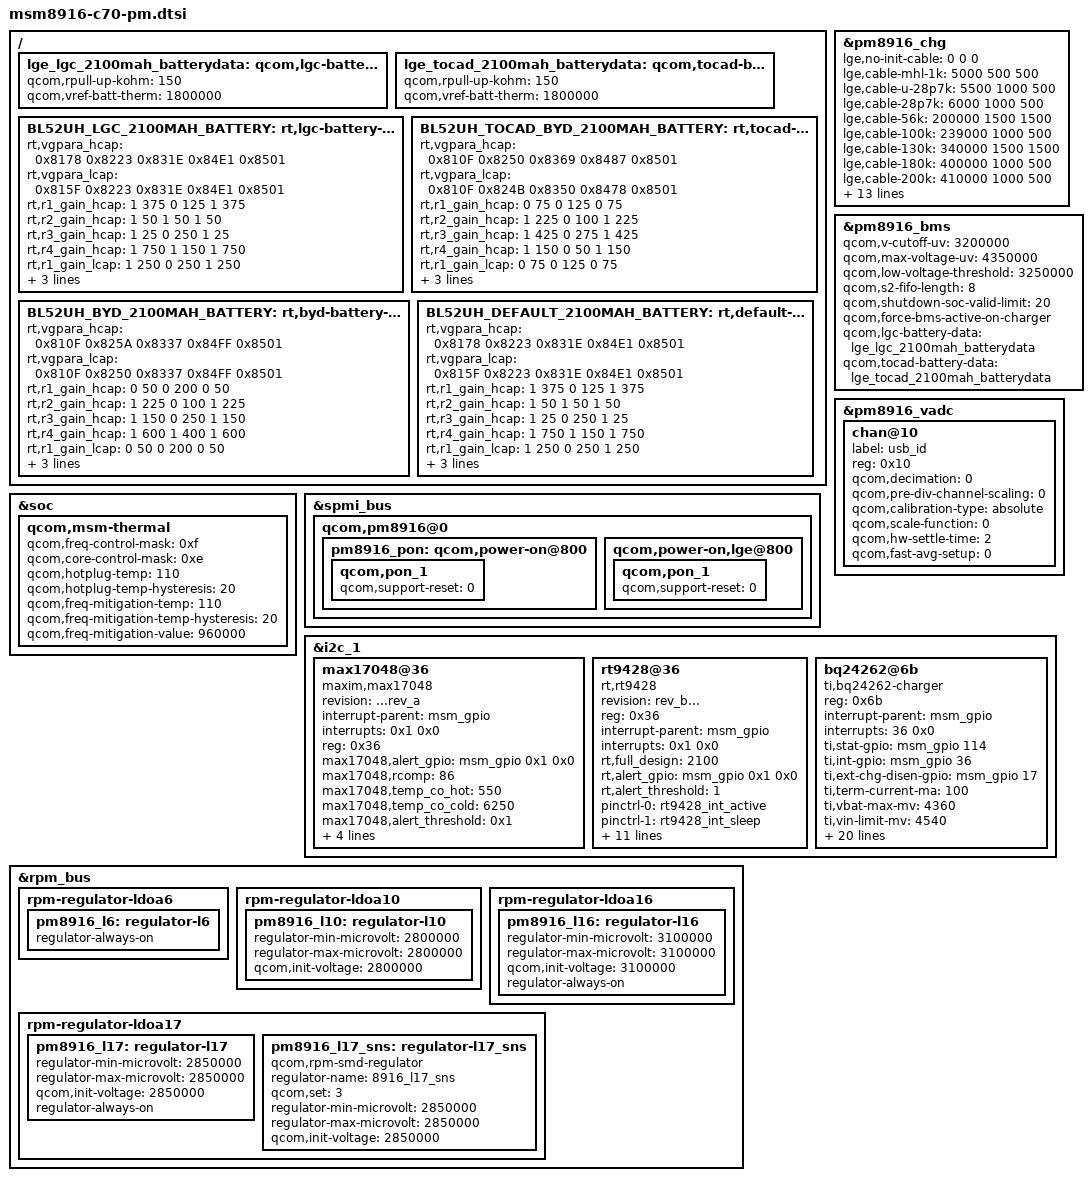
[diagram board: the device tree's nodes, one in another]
/* Copyright (c) 2012, Code Aurora Forum. All rights reserved.
 *
 * This program is free software; you can redistribute it and/or modify
* it under the terms of the GNU General Public License version 2 and
* only version 2 as published by the Free Software Foundation.
*
* This program is distributed in the hope that it will be useful,
* but WITHOUT ANY WARRANTY; without even the implied warranty of
* MERCHANTABILITY or FITNESS FOR A PARTICULAR PURPOSE.  See the
* GNU General Public License for more details.
*/

&pm8916_chg {
	status = "ok";

	lge,no-init-cable = <0 0 0>;
	lge,cable-mhl-1k = <5000 500 500>;
	lge,cable-u-28p7k = <5500 1000 500>;
	lge,cable-28p7k = <6000 1000 500>;
	lge,cable-56k = <200000 1500 1500>;
	lge,cable-100k = <239000 1000 500>;
	lge,cable-130k = <340000 1500 1500>;
	lge,cable-180k = <400000 1000 500>;
	lge,cable-200k = <410000 1000 500>;
	lge,cable-220k = <485000 1000 500>;
	lge,cable-270k = <560000 1000 500>;
	lge,cable-330k = <735000 1000 500>;
	lge,cable-620k = <955000 1000 500>;
	lge,cable-910k = <1140000 1500 1500>;
	lge,cable-none = <1900000 1000  500>;

	qcom,vddmax-mv = <4350>;
	qcom,vddsafe-mv = <4380>;
	qcom,vinmin-mv = <4470>;
	qcom,tchg-mins = <480>;
	qcom,btc-disabled = <1>;
	qcom,resume-soc = <98>;
	qcom,disable-vbatdet-based-recharge;
};

&soc {
	qcom,msm-thermal {
		qcom,freq-control-mask = <0xf>;
		qcom,core-control-mask = <0xe>;
		qcom,hotplug-temp = <110>;
		qcom,hotplug-temp-hysteresis = <20>;
		qcom,freq-mitigation-temp = <110>;
		qcom,freq-mitigation-temp-hysteresis = <20>;
		qcom,freq-mitigation-value = <960000>;
		};
};

&spmi_bus {
qcom,pm8916@0 {
	pm8916_pon: qcom,power-on@800 {
			qcom,pon_1 {
				qcom,support-reset = <0>;
			};
		};
	qcom,power-on,lge@800{
			 qcom,pon_1 {
				qcom,support-reset = <0>;
			};
		};
	};
};

/ {
	lge_lgc_2100mah_batterydata: qcom,lgc-battery-data {
		qcom,rpull-up-kohm = <150>;
		qcom,vref-batt-therm = <1800000>;

		#include "../msm8916-lge-common/batterydata_LGE_lgc_2100mAh_52UH.dtsi"
	};

	lge_tocad_2100mah_batterydata: qcom,tocad-battery-data {
		qcom,rpull-up-kohm = <150>;
		qcom,vref-batt-therm = <1800000>;

		#include "../msm8916-lge-common/batterydata_LGE_tocad_2100mAh_52UH.dtsi"
	};
};

/ {
	BL52UH_LGC_2100MAH_BATTERY: rt,lgc-battery-data {
		rt,vgpara_hcap = <0x8178 0x8223 0x831E 0x84E1 0x8501>;
		rt,vgpara_lcap = <0x815F 0x8223 0x831E 0x84E1 0x8501>;
		rt,r1_gain_hcap = < 1 375 0 125 1 375>;
		rt,r2_gain_hcap = < 1 50  1 50  1 50>;
		rt,r3_gain_hcap = < 1 25  0 250 1 25>;
		rt,r4_gain_hcap = < 1 750 1 150 1 750>;
		rt,r1_gain_lcap = < 1 250 0 250 1 250>;
		rt,r2_gain_lcap = < 1 50  1 50  1 50>;
		rt,r3_gain_lcap = < 1 25  0 250 1 25>;
		rt,r4_gain_lcap = < 1 750 1 150 1 750>;
	};

	BL52UH_TOCAD_BYD_2100MAH_BATTERY: rt,tocad-byd-battery-data {
		rt,vgpara_hcap = <0x810F 0x8250 0x8369 0x8487 0x8501>;
		rt,vgpara_lcap = <0x810F 0x824B 0x8350 0x8478 0x8501>;
		rt,r1_gain_hcap = < 0 75  0 125 0 75>;
		rt,r2_gain_hcap = < 1 225 0 100 1 225>;
		rt,r3_gain_hcap = < 1 425 0 275 1 425>;
		rt,r4_gain_hcap = < 1 150 0 50  1 150>;
		rt,r1_gain_lcap = < 0 75  0 125 0 75>;
		rt,r2_gain_lcap = < 1 200 0 25  1 200>;
		rt,r3_gain_lcap = < 1 300 0 325 1 300>;
		rt,r4_gain_lcap = < 1 75  0 75  1 75>;
	};

	BL52UH_BYD_2100MAH_BATTERY: rt,byd-battery-data {
		rt,vgpara_hcap = <0x810F 0x825A 0x8337 0x84FF 0x8501>;
		rt,vgpara_lcap = <0x810F 0x8250 0x8337 0x84FF 0x8501>;
		rt,r1_gain_hcap = < 0 50 0 200 0 50>;
		rt,r2_gain_hcap = < 1 225  0 100  1 225>;
		rt,r3_gain_hcap = < 1 150  0 250 1 150>;
		rt,r4_gain_hcap = < 1 600 1 400 1 600>;
		rt,r1_gain_lcap = < 0 50 0 200 0 50>;
		rt,r2_gain_lcap = < 1 190  1 90  1 190>;
		rt,r3_gain_lcap = < 1 150  0 250 1 150>;
		rt,r4_gain_lcap = < 1 600 1 400 1 600>;
	};

	BL52UH_DEFAULT_2100MAH_BATTERY: rt,default-battery-data {
		rt,vgpara_hcap = <0x8178 0x8223 0x831E 0x84E1 0x8501>;
		rt,vgpara_lcap = <0x815F 0x8223 0x831E 0x84E1 0x8501>;
		rt,r1_gain_hcap = < 1 375 0 125 1 375>;
		rt,r2_gain_hcap = < 1 50  1 50  1 50>;
		rt,r3_gain_hcap = < 1 25  0 250 1 25>;
		rt,r4_gain_hcap = < 1 750 1 150 1 750>;
		rt,r1_gain_lcap = < 1 250 0 250 1 250>;
		rt,r2_gain_lcap = < 1 50  1 50  1 50>;
		rt,r3_gain_lcap = < 1 25  0 250 1 25>;
		rt,r4_gain_lcap = < 1 750 1 150 1 750>;
	};
};

&pm8916_bms {
	status = "ok";
	qcom,v-cutoff-uv = <3200000>;
	qcom,max-voltage-uv = <4350000>;
	qcom,low-voltage-threshold = <3250000>;
	qcom,s2-fifo-length = <8>;
	qcom,shutdown-soc-valid-limit = <20>;
	qcom,force-bms-active-on-charger;
	qcom,lgc-battery-data = <&lge_lgc_2100mah_batterydata>;
	qcom,tocad-battery-data = <&lge_tocad_2100mah_batterydata>;
};

&pm8916_vadc {
	chan@10 {
		label = "usb_id";
		reg = <0x10>;
		qcom,decimation = <0>;
		qcom,pre-div-channel-scaling = <0>;
		qcom,calibration-type = "absolute";
		qcom,scale-function = <0>;
		qcom,hw-settle-time = <2>;
		qcom,fast-avg-setup = <0>;
	};
};

&i2c_1 {
	max17048@36 {
		status = "ok";
		revision = "...rev_a";
		compatible = "maxim,max17048";
		interrupt-parent = <&msm_gpio>;
		interrupts = <0x1 0x0>;
		reg = <0x36>;
		max17048,alert_gpio = <&msm_gpio 0x1 0x0>;
		max17048,rcomp = <86>;
		max17048,temp_co_hot = <550>;
		max17048,temp_co_cold = <6250>;
		max17048,alert_threshold = <0x1>;
		max17048,full_design = <3200>;
		max17048,empty = <0>;
		pinctrl-names = "default", "sleep";
		pinctrl-0 = <&max17048_int_active>;
		pinctrl-1 = <&max17048_int_sleep>;
	};

	rt9428@36 {
		compatible = "rt,rt9428";
		status = "ok";
		revision = "rev_b...";
		reg = <0x36>;
		interrupt-parent = <&msm_gpio>;
		interrupts = <0x1 0x0>;
		rt,full_design= <2100>;
		rt,alert_gpio = <&msm_gpio 0x1 0x0>;
		rt,alert_threshold = <1>;
		/* Pins config setting */
		pinctrl-names = "default", "sleep";
		pinctrl-0 = <&rt9428_int_active>;
		pinctrl-1 = <&rt9428_int_sleep>;
		rt,soc_comp = <0>;
		rt,vgcomp0 = <0xAB>;
		rt,temp_base = <5 5 25 45>;
		rt,lgc-battery-data = <&BL52UH_LGC_2100MAH_BATTERY>;
		rt,tocad-byd-battery-data = <&BL52UH_TOCAD_BYD_2100MAH_BATTERY>;
		rt,byd-battery-data = <&BL52UH_BYD_2100MAH_BATTERY>;
		rt,default-battery-data = <&BL52UH_DEFAULT_2100MAH_BATTERY>;
	};

	bq24262@6b {
		status = "ok";
		compatible = "ti,bq24262-charger";
		reg = <0x6b>;
		interrupt-parent = <&msm_gpio>;
		interrupts = <36 0x0>;
		ti,stat-gpio = <&msm_gpio 114 0>;
		ti,int-gpio = <&msm_gpio 36 0>;
		ti,ext-chg-disen-gpio = <&msm_gpio 17 0>;
		ti,term-current-ma = <100>;
		ti,vbat-max-mv = <4360>;		/* Step unit 20 mV, battery available voltage(x = 4.375) : x-0.025 ~ x ~ x+0.025 */
		ti,vin-limit-mv = <4540>;
		/* Pins config setting */
		pinctrl-names = "default", "sleep";
		pinctrl-0 = <&bq24262_int_active &bq24262_ext_stat_active>;
		pinctrl-1 = <&bq24262_int_sleep &bq24262_ext_stat_sleep>;

/* Each model is defferently value */
		lge,no-init-cable = <0 0 0>;
		lge,cable-mhl-1k = <5000 500 500>;
		lge,cable-u-28p7k = <5500 1000 500>;
		lge,cable-28p7k = <6000 1000 500>;
		lge,cable-56k = <200000 1500 1500>;
		lge,cable-100k = <239000 1000 500>;
		lge,cable-130k = <340000 1500 1500>;
		lge,cable-180k = <400000 1000 500>;
		lge,cable-200k = <410000 1000 500>;
		lge,cable-220k = <485000 1000 500>;
		lge,cable-270k = <560000 1000 500>;
		lge,cable-330k = <735000 1000 500>;
		lge,cable-620k = <955000 1000 500>;
		lge,cable-910k = <1140000 1500 1500>;
		lge,cable-none = <1900000 1000  500>;

		qcom,bq24262-vadc = <&pm8916_vadc>;
	};
};

&rpm_bus {
	rpm-regulator-ldoa6 {
		status = "okay";
		pm8916_l6: regulator-l6 {
			regulator-always-on;
			status = "okay";
		};
	};

	rpm-regulator-ldoa10 {
		status = "okay";
		pm8916_l10: regulator-l10 {
			regulator-min-microvolt = <2800000>;
			regulator-max-microvolt = <2800000>;
			qcom,init-voltage = <2800000>;
			//regulator-always-on;
			status = "okay";
		};
	};

	rpm-regulator-ldoa16 {
		status = "okay";
		pm8916_l16: regulator-l16 {
			regulator-min-microvolt = <3100000>;
			regulator-max-microvolt = <3100000>;
			qcom,init-voltage = <3100000>;
			regulator-always-on;
			status = "okay";
		};
	};

	rpm-regulator-ldoa17 {
		status = "okay";
		pm8916_l17: regulator-l17 {
			regulator-min-microvolt = <2850000>;
			regulator-max-microvolt = <2850000>;
			qcom,init-voltage = <2850000>;
			regulator-always-on;
			status = "okay";
		};

		pm8916_l17_sns: regulator-l17_sns {
			status = "ok";
			compatible = "qcom,rpm-smd-regulator";
			regulator-name = "8916_l17_sns";
			qcom,set = <3>;
			regulator-min-microvolt = <2850000>;
			regulator-max-microvolt = <2850000>;
			qcom,init-voltage = <2850000>;
		};
	};
};
